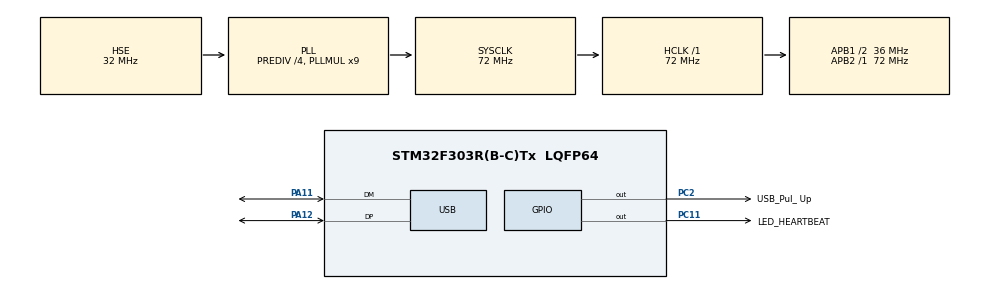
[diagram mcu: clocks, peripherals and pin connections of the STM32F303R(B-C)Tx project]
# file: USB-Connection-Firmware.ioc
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Mcu.Family=STM32F3
Mcu.Name=STM32F303R(B-C)Tx
Mcu.Package=LQFP64
NVIC.PriorityGroup=NVIC_PRIORITYGROUP_4
NVIC.USB_HP_CAN_TX_IRQn=true\:0\:0\:false\:false\:true\:true\:true\:true
NVIC.USB_LP_CAN_RX0_IRQn=true\:0\:0\:false\:false\:true\:false\:true\:true
PA11.Mode=Device
PA11.Signal=USB_DM
PA12.Mode=Device
PA12.Signal=USB_DP
PA13.Mode=Serial_Wire
PA13.Signal=SYS_JTMS-SWDIO
PA14.Mode=Serial_Wire
PA14.Signal=SYS_JTCK-SWCLK
PA8.Signal=RCC_MCO
PC11.GPIO_Label=LED_HEARTBEAT
PC11.Signal=GPIO_Output
PC2.GPIO_Label=USB_Pul_ Up
PC2.Signal=GPIO_Output
PF0-OSC_IN.Mode=HSE-External-Oscillator
PF0-OSC_IN.Signal=RCC_OSC_IN
PF1-OSC_OUT.Mode=HSE-External-Oscillator
PF1-OSC_OUT.Signal=RCC_OSC_OUT
ProjectManager.HeapSize=0x800
ProjectManager.StackSize=0x400
ProjectManager.TargetToolchain=STM32CubeIDE
RCC.AHBFreq_Value=72000000
RCC.APB1CLKDivider=RCC_HCLK_DIV2
RCC.APB1Freq_Value=36000000
RCC.APB1TimFreq_Value=72000000
RCC.APB2Freq_Value=72000000
RCC.APB2TimFreq_Value=72000000
RCC.CortexFreq_Value=72000000
RCC.HCLKFreq_Value=72000000
RCC.HSE_VALUE=32000000
RCC.HSI_VALUE=8000000
RCC.LSE_VALUE=32768
RCC.PLLMUL=RCC_PLL_MUL9
RCC.PRESCALERUSB=RCC_USBCLKSOURCE_PLL_DIV1_5
RCC.RCC_MCOSource=RCC_MCO1SOURCE_HSE
RCC.RCC_PLLsource_Clock_Source_FROM_HSE=RCC_HSE_PREDIV_DIV4
RCC.SYSCLKFreq_VALUE=72000000
RCC.SYSCLKSourceVirtual=RCC_SYSCLKSOURCE_PLLCLK
RCC.USBFreq_Value=48000000
USB_DEVICE.CLASS_NAME_FS=CDC
USB_DEVICE.VirtualMode=Cdc
USB_DEVICE.VirtualModeFS=Cdc_FS
VP_USB_DEVICE_VS_USB_DEVICE_CDC_FS.Mode=CDC_FS
board=custom

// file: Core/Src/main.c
/* USER CODE BEGIN Header */
/**
  ******************************************************************************
  * @file           : main.c
  * @brief          : Main program body
  ******************************************************************************
  * @attention
  *
  * Copyright (c) 2026 STMicroelectronics.
  * All rights reserved.
  *
  ******************************************************************************
  */
/* USER CODE END Header */
#include "main.h"
#include "usb_device.h"

/* USER CODE BEGIN Includes */
#include "usbd_cdc_if.h" // Required for USB Transmission
/* USER CODE END Includes */

void SystemClock_Config(void);
static void MX_GPIO_Init(void);

int main(void)
{

  /* MCU Configuration--------------------------------------------------------*/

  /* Reset of all peripherals, Initializes the Flash interface and the Systick. */
  HAL_Init();

  /* Configure the system clock */
  SystemClock_Config();

  /* Initialize all configured peripherals */
  MX_GPIO_Init();
  MX_USB_DEVICE_Init();
  /* USER CODE BEGIN 2 */

  // --- CRITICAL FIX 1: Turn on the USB Pull-Up Resistor (PC2) ---
  // Your schematic shows PC2 controls the USB connection.
  // Setting this High tells the computer "I am plugged in".
  HAL_GPIO_WritePin(GPIOC, GPIO_PIN_2, GPIO_PIN_SET);

  // Wait a moment for the PC to recognize the voltage change
  HAL_Delay(1000);

  /* USER CODE END 2 */

  /* Infinite loop */
  /* USER CODE BEGIN WHILE */
  while (1)
  {
    /* USER CODE BEGIN WHILE_LOOP_LOGIC */

    // --- DIAGNOSTIC 1: Heartbeat LED ---
    // Toggle PC11. If this blinks, your Crystal/Clock is 100% working.
    HAL_GPIO_TogglePin(GPIOC, GPIO_PIN_11);

    // --- DIAGNOSTIC 2: Send Data ---
    // Send "BMS Alive!" to the PC
    CDC_Transmit_FS((uint8_t*)"BMS Alive!\r\n", 12);

    // Speed: 500ms delay = 1 blink per second
    HAL_Delay(500);

    /* USER CODE END WHILE_LOOP_LOGIC */
    /* USER CODE END WHILE */

  }
}

void SystemClock_Config(void)
{
  RCC_OscInitTypeDef RCC_OscInitStruct = {0};
  RCC_ClkInitTypeDef RCC_ClkInitStruct = {0};
  RCC_PeriphCLKInitTypeDef PeriphClkInit = {0};

  /** Initializes the RCC Oscillators according to the specified parameters
  * in the RCC_OscInitTypeDef structure.
  */
  RCC_OscInitStruct.OscillatorType = RCC_OSCILLATORTYPE_HSE;
  RCC_OscInitStruct.HSEState = RCC_HSE_ON;
  RCC_OscInitStruct.HSEPredivValue = RCC_HSE_PREDIV_DIV4;
  RCC_OscInitStruct.HSIState = RCC_HSI_ON;
  RCC_OscInitStruct.PLL.PLLState = RCC_PLL_ON;
  RCC_OscInitStruct.PLL.PLLSource = RCC_PLLSOURCE_HSE;
  RCC_OscInitStruct.PLL.PLLMUL = RCC_PLL_MUL9;
  if (HAL_RCC_OscConfig(&RCC_OscInitStruct) != HAL_OK)
  {
    Error_Handler();
  }

  /** Initializes the CPU, AHB and APB buses clocks
  */
  RCC_ClkInitStruct.ClockType = RCC_CLOCKTYPE_HCLK|RCC_CLOCKTYPE_SYSCLK
                              |RCC_CLOCKTYPE_PCLK1|RCC_CLOCKTYPE_PCLK2;
  RCC_ClkInitStruct.SYSCLKSource = RCC_SYSCLKSOURCE_PLLCLK;
  RCC_ClkInitStruct.AHBCLKDivider = RCC_SYSCLK_DIV1;
  RCC_ClkInitStruct.APB1CLKDivider = RCC_HCLK_DIV2;
  RCC_ClkInitStruct.APB2CLKDivider = RCC_HCLK_DIV1;

  if (HAL_RCC_ClockConfig(&RCC_ClkInitStruct, FLASH_LATENCY_2) != HAL_OK)
  {
    Error_Handler();
  }
  PeriphClkInit.PeriphClockSelection = RCC_PERIPHCLK_USB;
  PeriphClkInit.USBClockSelection = RCC_USBCLKSOURCE_PLL_DIV1_5;
  if (HAL_RCCEx_PeriphCLKConfig(&PeriphClkInit) != HAL_OK)
  {
    Error_Handler();
  }
}

static void MX_GPIO_Init(void)
{
  GPIO_InitTypeDef GPIO_InitStruct = {0};

  /* GPIO Ports Clock Enable */
  __HAL_RCC_GPIOF_CLK_ENABLE();
  __HAL_RCC_GPIOC_CLK_ENABLE();
  __HAL_RCC_GPIOA_CLK_ENABLE();

  /*Configure GPIO pin Output Level */
  HAL_GPIO_WritePin(GPIOC, USB_Pul__Up_Pin|LED_HEARTBEAT_Pin, GPIO_PIN_RESET);

  /*Configure GPIO pins : USB_Pul__Up_Pin LED_HEARTBEAT_Pin */
  GPIO_InitStruct.Pin = USB_Pul__Up_Pin|LED_HEARTBEAT_Pin;
  GPIO_InitStruct.Mode = GPIO_MODE_OUTPUT_PP;
  GPIO_InitStruct.Pull = GPIO_NOPULL;
  GPIO_InitStruct.Speed = GPIO_SPEED_FREQ_LOW;
  HAL_GPIO_Init(GPIOC, &GPIO_InitStruct);

  /*Configure GPIO pin : PA8 */
  GPIO_InitStruct.Pin = GPIO_PIN_8;
  GPIO_InitStruct.Mode = GPIO_MODE_AF_PP;
  GPIO_InitStruct.Pull = GPIO_NOPULL;
  GPIO_InitStruct.Speed = GPIO_SPEED_FREQ_LOW;
  GPIO_InitStruct.Alternate = GPIO_AF0_MCO;
  HAL_GPIO_Init(GPIOA, &GPIO_InitStruct);

}

void Error_Handler(void)
{
  __disable_irq();
  while (1)
  {
  }
}
